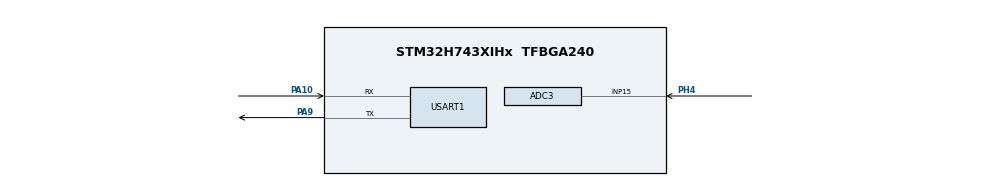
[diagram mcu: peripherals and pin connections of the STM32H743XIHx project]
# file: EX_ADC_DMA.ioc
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ADC3.Channel-2\#ChannelRegularConversion=ADC_CHANNEL_15
ADC3.ClockPrescalerADC3=ADC_CLOCK_ASYNC_DIV256
ADC3.ContinuousConvMode=ENABLE
ADC3.ConversionDataManagement=ADC_CONVERSIONDATA_DMA_CIRCULAR
ADC3.NbrOfConversionFlag=1
ADC3.OffsetNumber-2\#ChannelRegularConversion=ADC_OFFSET_NONE
ADC3.OffsetSignedSaturation-2\#ChannelRegularConversion=DISABLE
ADC3.Overrun=ADC_OVR_DATA_OVERWRITTEN
ADC3.Rank-2\#ChannelRegularConversion=1
ADC3.SamplingTime-2\#ChannelRegularConversion=ADC_SAMPLETIME_810CYCLES_5
Bdma.ADC3.0.Direction=DMA_PERIPH_TO_MEMORY
Bdma.ADC3.0.EventEnable=DISABLE
Bdma.ADC3.0.Instance=BDMA_Channel0
Bdma.ADC3.0.MemDataAlignment=DMA_MDATAALIGN_HALFWORD
Bdma.ADC3.0.MemInc=DMA_MINC_ENABLE
Bdma.ADC3.0.Mode=DMA_CIRCULAR
Bdma.ADC3.0.PeriphDataAlignment=DMA_PDATAALIGN_HALFWORD
Bdma.ADC3.0.PeriphInc=DMA_PINC_DISABLE
Bdma.ADC3.0.Polarity=HAL_DMAMUX_REQ_GEN_RISING
Bdma.ADC3.0.Priority=DMA_PRIORITY_LOW
Bdma.ADC3.0.RequestNumber=1
Bdma.ADC3.0.SignalID=NONE
Bdma.ADC3.0.SyncEnable=DISABLE
Bdma.ADC3.0.SyncPolarity=HAL_DMAMUX_SYNC_NO_EVENT
Bdma.ADC3.0.SyncRequestNumber=1
Bdma.ADC3.0.SyncSignalID=NONE
Bdma.Request0=ADC3
Bdma.RequestsNb=1
CORTEX_M7.AccessPermission_S-Cortex_Memory_Protection_Unit_Region1_Settings_S=MPU_REGION_FULL_ACCESS
CORTEX_M7.AccessPermission_S-Cortex_Memory_Protection_Unit_Region2_Settings_S=MPU_REGION_FULL_ACCESS
CORTEX_M7.AccessPermission_S-Cortex_Memory_Protection_Unit_Region3_Settings_S=MPU_REGION_FULL_ACCESS
CORTEX_M7.AccessPermission_Spec=MPU_REGION_FULL_ACCESS
CORTEX_M7.BaseAddress_S-Cortex_Memory_Protection_Unit_Region1_Settings_S=0x24000000
CORTEX_M7.BaseAddress_S-Cortex_Memory_Protection_Unit_Region2_Settings_S=0x30000000
CORTEX_M7.BaseAddress_S-Cortex_Memory_Protection_Unit_Region3_Settings_S=0x38000000
CORTEX_M7.BaseAddress_Spec=0x20000000
CORTEX_M7.CPU_DCache=Enabled
CORTEX_M7.CPU_ICache=Enabled
CORTEX_M7.DisableExec_Spec=MPU_INSTRUCTION_ACCESS_ENABLE
CORTEX_M7.Enable_S-Cortex_Memory_Protection_Unit_Region1_Settings_S=MPU_REGION_ENABLE
CORTEX_M7.Enable_S-Cortex_Memory_Protection_Unit_Region2_Settings_S=MPU_REGION_ENABLE
CORTEX_M7.Enable_S-Cortex_Memory_Protection_Unit_Region3_Settings_S=MPU_REGION_ENABLE
CORTEX_M7.IsBufferable_S-Cortex_Memory_Protection_Unit_Region1_Settings_S=MPU_ACCESS_BUFFERABLE
CORTEX_M7.IsBufferable_S-Cortex_Memory_Protection_Unit_Region2_Settings_S=MPU_ACCESS_BUFFERABLE
CORTEX_M7.IsBufferable_S-Cortex_Memory_Protection_Unit_Region3_Settings_S=MPU_ACCESS_BUFFERABLE
CORTEX_M7.IsBufferable_Spec=MPU_ACCESS_BUFFERABLE
CORTEX_M7.IsCacheable_S-Cortex_Memory_Protection_Unit_Region1_Settings_S=MPU_ACCESS_CACHEABLE
CORTEX_M7.IsCacheable_S-Cortex_Memory_Protection_Unit_Region2_Settings_S=MPU_ACCESS_CACHEABLE
CORTEX_M7.IsCacheable_S-Cortex_Memory_Protection_Unit_Region3_Settings_S=MPU_ACCESS_CACHEABLE
CORTEX_M7.IsCacheable_Spec=MPU_ACCESS_CACHEABLE
CORTEX_M7.IsShareable_Spec=MPU_ACCESS_NOT_SHAREABLE
CORTEX_M7.Size_S-Cortex_Memory_Protection_Unit_Region1_Settings_S=MPU_REGION_SIZE_512KB
CORTEX_M7.Size_S-Cortex_Memory_Protection_Unit_Region2_Settings_S=MPU_REGION_SIZE_512KB
CORTEX_M7.Size_S-Cortex_Memory_Protection_Unit_Region3_Settings_S=MPU_REGION_SIZE_64KB
CORTEX_M7.Size_Spec=MPU_REGION_SIZE_128KB
CORTEX_M7.SubRegionDisable_Spec=0x00
CORTEX_M7.default_mode_Activation=1
Dma.Request0=USART1_RX
Dma.USART1_RX.0.Direction=DMA_PERIPH_TO_MEMORY
Dma.USART1_RX.0.EventEnable=DISABLE
Dma.USART1_RX.0.FIFOMode=DMA_FIFOMODE_DISABLE
Dma.USART1_RX.0.Instance=DMA1_Stream0
Dma.USART1_RX.0.MemDataAlignment=DMA_MDATAALIGN_BYTE
Dma.USART1_RX.0.MemInc=DMA_MINC_ENABLE
Dma.USART1_RX.0.Mode=DMA_NORMAL
Dma.USART1_RX.0.PeriphDataAlignment=DMA_PDATAALIGN_BYTE
Dma.USART1_RX.0.PeriphInc=DMA_PINC_DISABLE
Dma.USART1_RX.0.Polarity=HAL_DMAMUX_REQ_GEN_RISING
Dma.USART1_RX.0.Priority=DMA_PRIORITY_LOW
Dma.USART1_RX.0.RequestNumber=1
Dma.USART1_RX.0.SignalID=NONE
Dma.USART1_RX.0.SyncEnable=DISABLE
Dma.USART1_RX.0.SyncPolarity=HAL_DMAMUX_SYNC_NO_EVENT
Dma.USART1_RX.0.SyncRequestNumber=1
Dma.USART1_RX.0.SyncSignalID=NONE
Mcu.Family=STM32H7
Mcu.Name=STM32H743XIHx
Mcu.Package=TFBGA240
NVIC.BDMA_Channel0_IRQn=true\:0\:0\:false\:false\:true\:false\:true\:true
NVIC.DMA1_Stream0_IRQn=true\:0\:0\:false\:false\:true\:false\:true\:true
NVIC.PriorityGroup=NVIC_PRIORITYGROUP_4
NVIC.USART1_IRQn=true\:0\:0\:false\:false\:true\:true\:true\:true
PA10.Mode=Asynchronous
PA10.Signal=USART1_RX
PA13\ (JTMS/SWDIO).Mode=Serial_Wire
PA13\ (JTMS/SWDIO).Signal=DEBUG_JTMS-SWDIO
PA14\ (JTCK/SWCLK).Mode=Serial_Wire
PA14\ (JTCK/SWCLK).Signal=DEBUG_JTCK-SWCLK
PA9.Mode=Asynchronous
PA9.Signal=USART1_TX
PC14-OSC32_IN\ (OSC32_IN).Mode=LSE-External-Oscillator
PC14-OSC32_IN\ (OSC32_IN).Signal=RCC_OSC32_IN
PC15-OSC32_OUT\ (OSC32_OUT).Mode=LSE-External-Oscillator
PC15-OSC32_OUT\ (OSC32_OUT).Signal=RCC_OSC32_OUT
PH0-OSC_IN\ (PH0).Mode=HSE-External-Oscillator
PH0-OSC_IN\ (PH0).Signal=RCC_OSC_IN
PH1-OSC_OUT\ (PH1).Mode=HSE-External-Oscillator
PH1-OSC_OUT\ (PH1).Signal=RCC_OSC_OUT
PH4.Mode=IN15-Single-Ended
PH4.Signal=ADC3_INP15
ProjectManager.HeapSize=0x200
ProjectManager.StackSize=0x400
ProjectManager.TargetToolchain=MDK-ARM V5.32
RCC.ADCFreq_Value=75000000
RCC.APB1Freq_Value=120000000
RCC.APB2Freq_Value=120000000
RCC.APB3Freq_Value=120000000
RCC.APB4Freq_Value=120000000
RCC.CortexFreq_Value=480000000
RCC.D1PPRE=RCC_APB3_DIV2
RCC.D2PPRE1=RCC_APB1_DIV2
RCC.D2PPRE2=RCC_APB2_DIV2
RCC.D3PPRE=RCC_APB4_DIV2
RCC.DIVM1=5
RCC.DIVM2=2
RCC.DIVN1=192
RCC.DIVN2=12
RCC.HCLKFreq_Value=240000000
RCC.HPRE=RCC_HCLK_DIV2
RCC.PLL2FRACN=0
RCC.PLLFRACN=0
RCC.PLLSourceVirtual=RCC_PLLSOURCE_HSE
RCC.SYSCLKFreq_VALUE=480000000
RCC.SYSCLKSource=RCC_SYSCLKSOURCE_PLLCLK
RCC.USBFreq_Value=480000000
USART1.VirtualMode-Asynchronous=VM_ASYNC
VP_MEMORYMAP_VS_MEMORYMAP.Mode=CurAppReg
board=custom

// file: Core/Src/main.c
/* USER CODE BEGIN Header */
/**
  ******************************************************************************
  * @file           : main.c
  * @brief          : Main program body
  ******************************************************************************
  * @attention
  *
  * Copyright (c) 2026 STMicroelectronics.
  * All rights reserved.
  *
  * This software is licensed under terms that can be found in the LICENSE file
  * in the root directory of this software component.
  * If no LICENSE file comes with this software, it is provided AS-IS.
  *
  ******************************************************************************
  */
/* USER CODE END Header */
#include "main.h"
#include "adc.h"
#include "bdma.h"
#include "dma.h"
#include "usart.h"
#include "gpio.h"

/* USER CODE BEGIN Includes */
#include "bsp_system.h"
/* USER CODE END Includes */

void SystemClock_Config(void);
static void MPU_Config(void);

int main(void)
{

  /* MPU Configuration--------------------------------------------------------*/
  MPU_Config();

  /* Enable the CPU Cache */

  /* Enable I-Cache---------------------------------------------------------*/
  SCB_EnableICache();

  /* Enable D-Cache---------------------------------------------------------*/
  SCB_EnableDCache();

  /* MCU Configuration--------------------------------------------------------*/

  /* Reset of all peripherals, Initializes the Flash interface and the Systick. */
  HAL_Init();

  /* Configure the system clock */
  SystemClock_Config();

  /* Initialize all configured peripherals */
  MX_GPIO_Init();
  MX_DMA_Init();
  MX_BDMA_Init();
  MX_USART1_UART_Init();
  MX_ADC3_Init();
  /* USER CODE BEGIN 2 */
	Uart_Init();
	EX_ADC_Init();
  /* USER CODE END 2 */

  /* Infinite loop */
  /* USER CODE BEGIN WHILE */
  while (1)
  {
		ADC_proc();
		uart_proc();
		HAL_Delay(500);

    /* USER CODE END WHILE */

  }
}

void SystemClock_Config(void)
{
  RCC_OscInitTypeDef RCC_OscInitStruct = {0};
  RCC_ClkInitTypeDef RCC_ClkInitStruct = {0};

  /** Supply configuration update enable
  */
  HAL_PWREx_ConfigSupply(PWR_LDO_SUPPLY);

  /** Configure the main internal regulator output voltage
  */
  __HAL_PWR_VOLTAGESCALING_CONFIG(PWR_REGULATOR_VOLTAGE_SCALE0);

  while(!__HAL_PWR_GET_FLAG(PWR_FLAG_VOSRDY)) {}

  /** Initializes the RCC Oscillators according to the specified parameters
  * in the RCC_OscInitTypeDef structure.
  */
  RCC_OscInitStruct.OscillatorType = RCC_OSCILLATORTYPE_HSE;
  RCC_OscInitStruct.HSEState = RCC_HSE_ON;
  RCC_OscInitStruct.PLL.PLLState = RCC_PLL_ON;
  RCC_OscInitStruct.PLL.PLLSource = RCC_PLLSOURCE_HSE;
  RCC_OscInitStruct.PLL.PLLM = 5;
  RCC_OscInitStruct.PLL.PLLN = 192;
  RCC_OscInitStruct.PLL.PLLP = 2;
  RCC_OscInitStruct.PLL.PLLQ = 2;
  RCC_OscInitStruct.PLL.PLLR = 2;
  RCC_OscInitStruct.PLL.PLLRGE = RCC_PLL1VCIRANGE_2;
  RCC_OscInitStruct.PLL.PLLVCOSEL = RCC_PLL1VCOWIDE;
  RCC_OscInitStruct.PLL.PLLFRACN = 0;
  if (HAL_RCC_OscConfig(&RCC_OscInitStruct) != HAL_OK)
  {
    Error_Handler();
  }

  /** Initializes the CPU, AHB and APB buses clocks
  */
  RCC_ClkInitStruct.ClockType = RCC_CLOCKTYPE_HCLK|RCC_CLOCKTYPE_SYSCLK
                              |RCC_CLOCKTYPE_PCLK1|RCC_CLOCKTYPE_PCLK2
                              |RCC_CLOCKTYPE_D3PCLK1|RCC_CLOCKTYPE_D1PCLK1;
  RCC_ClkInitStruct.SYSCLKSource = RCC_SYSCLKSOURCE_PLLCLK;
  RCC_ClkInitStruct.SYSCLKDivider = RCC_SYSCLK_DIV1;
  RCC_ClkInitStruct.AHBCLKDivider = RCC_HCLK_DIV2;
  RCC_ClkInitStruct.APB3CLKDivider = RCC_APB3_DIV2;
  RCC_ClkInitStruct.APB1CLKDivider = RCC_APB1_DIV2;
  RCC_ClkInitStruct.APB2CLKDivider = RCC_APB2_DIV2;
  RCC_ClkInitStruct.APB4CLKDivider = RCC_APB4_DIV2;

  if (HAL_RCC_ClockConfig(&RCC_ClkInitStruct, FLASH_LATENCY_4) != HAL_OK)
  {
    Error_Handler();
  }
}

 /* MPU Configuration */

void MPU_Config(void)
{
  MPU_Region_InitTypeDef MPU_InitStruct = {0};

  /* Disables the MPU */
  HAL_MPU_Disable();

  /** Initializes and configures the Region and the memory to be protected
  */
  MPU_InitStruct.Enable = MPU_REGION_ENABLE;
  MPU_InitStruct.Number = MPU_REGION_NUMBER0;
  MPU_InitStruct.BaseAddress = 0x20000000;
  MPU_InitStruct.Size = MPU_REGION_SIZE_128KB;
  MPU_InitStruct.SubRegionDisable = 0x00;
  MPU_InitStruct.TypeExtField = MPU_TEX_LEVEL0;
  MPU_InitStruct.AccessPermission = MPU_REGION_FULL_ACCESS;
  MPU_InitStruct.DisableExec = MPU_INSTRUCTION_ACCESS_ENABLE;
  MPU_InitStruct.IsShareable = MPU_ACCESS_NOT_SHAREABLE;
  MPU_InitStruct.IsCacheable = MPU_ACCESS_CACHEABLE;
  MPU_InitStruct.IsBufferable = MPU_ACCESS_BUFFERABLE;

  HAL_MPU_ConfigRegion(&MPU_InitStruct);

  /** Initializes and configures the Region and the memory to be protected
  */
  MPU_InitStruct.Number = MPU_REGION_NUMBER1;
  MPU_InitStruct.BaseAddress = 0x24000000;
  MPU_InitStruct.Size = MPU_REGION_SIZE_512KB;
  MPU_InitStruct.SubRegionDisable = 0x0;

  HAL_MPU_ConfigRegion(&MPU_InitStruct);

  /** Initializes and configures the Region and the memory to be protected
  */
  MPU_InitStruct.Number = MPU_REGION_NUMBER2;
  MPU_InitStruct.BaseAddress = 0x30000000;

  HAL_MPU_ConfigRegion(&MPU_InitStruct);

  /** Initializes and configures the Region and the memory to be protected
  */
  MPU_InitStruct.Number = MPU_REGION_NUMBER3;
  MPU_InitStruct.BaseAddress = 0x38000000;
  MPU_InitStruct.Size = MPU_REGION_SIZE_64KB;

  HAL_MPU_ConfigRegion(&MPU_InitStruct);
  /* Enables the MPU */
  HAL_MPU_Enable(MPU_PRIVILEGED_DEFAULT);

}

void Error_Handler(void)
{
  __disable_irq();
  while (1)
  {
  }
}
